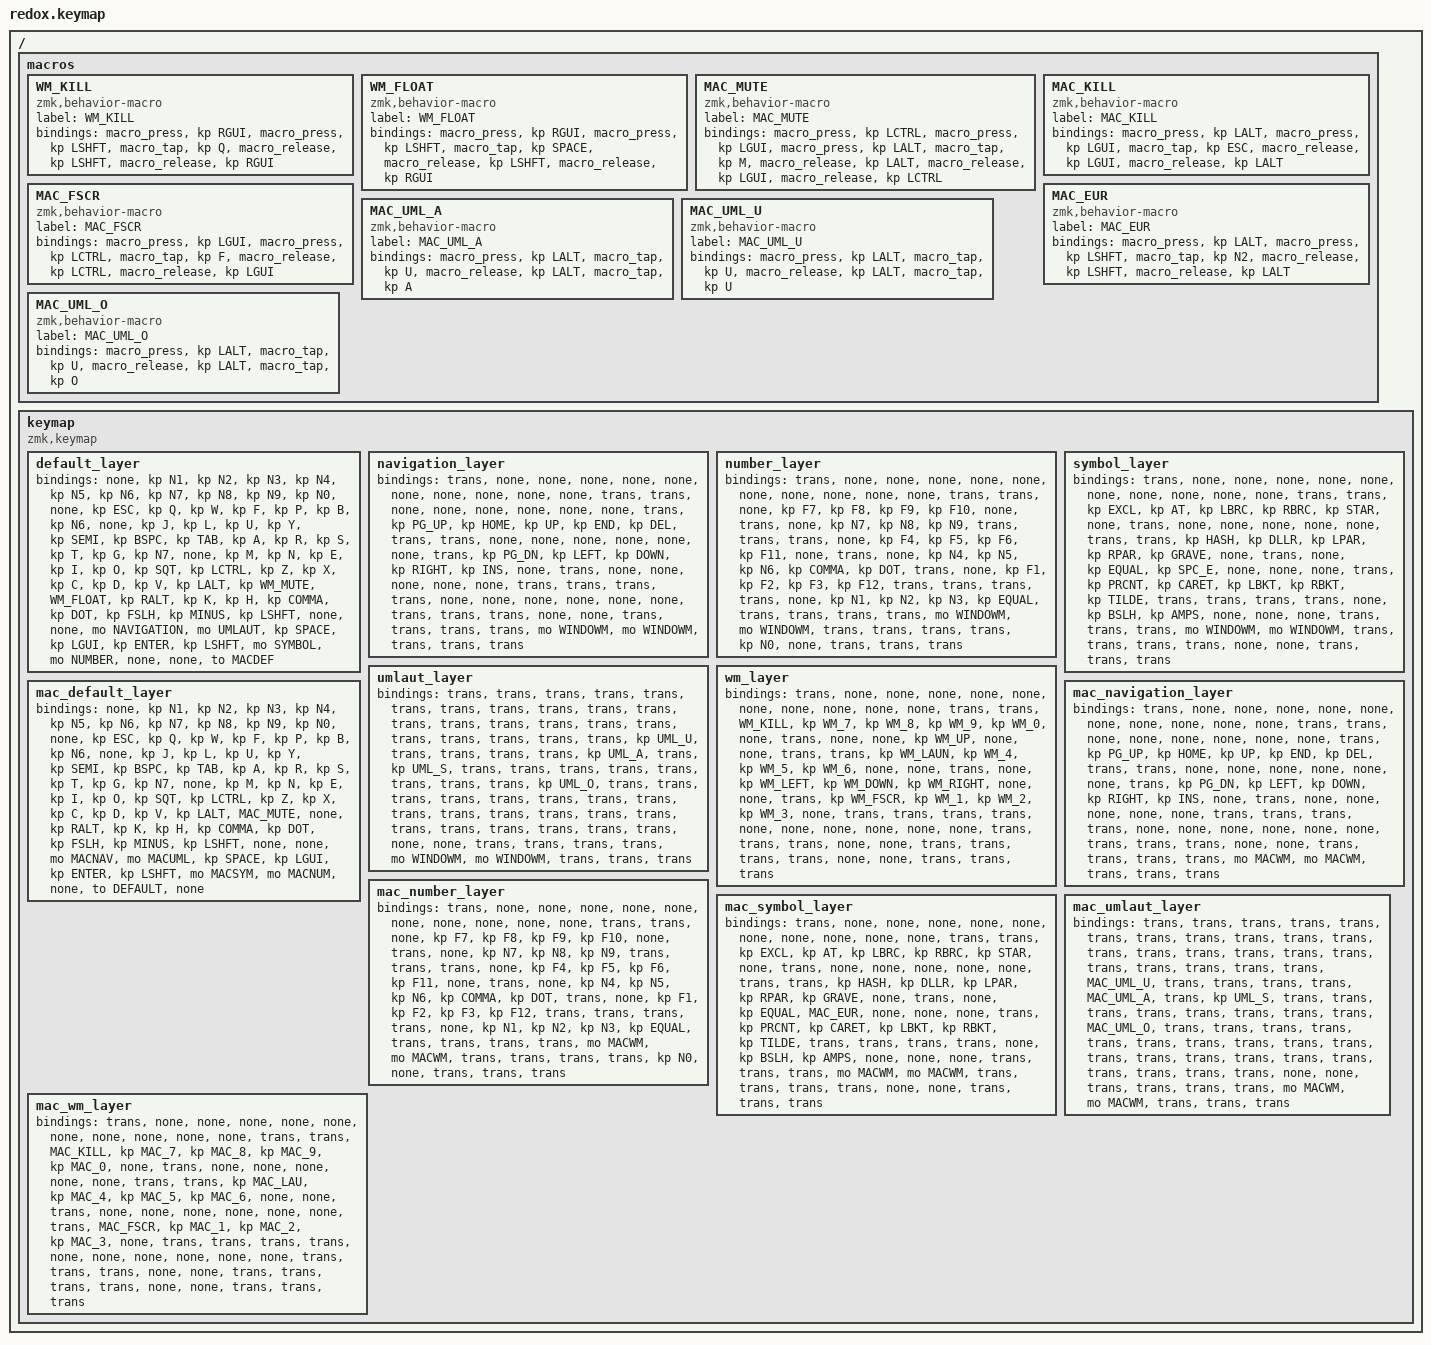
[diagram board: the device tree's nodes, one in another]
/*
 * Copyright (c) 2021 The ZMK Contributors
 *
 * SPDX-License-Identifier: MIT
 */

#include <behaviors.dtsi>
#include <dt-bindings/zmk/keys.h>
#include <dt-bindings/zmk/bt.h>
#include <dt-bindings/zmk/ext_power.h>
#include <dt-bindings/zmk/outputs.h>

#define UML_A RA(Q)
#define UML_S RA(S)
#define UML_U RA(Y)
#define UML_O RA(P)

#define SPC_E RA(N5)

#define WM_MUTE LG(M)

#define WM_UP LG(UP)
#define WM_DOWN LG(DOWN)
#define WM_LEFT LG(LEFT)
#define WM_RIGHT LG(RIGHT)

#define WM_1 LG(N1)
#define WM_2 LG(N2)
#define WM_3 LG(N3)
#define WM_4 LG(N4)
#define WM_5 LG(N5)
#define WM_6 LG(N6)
#define WM_7 LG(N7)
#define WM_8 LG(N8)
#define WM_9 LG(N9)
#define WM_0 LG(N0)

#define MAC_1 LC(N1)
#define MAC_2 LC(N2)
#define MAC_3 LC(N3)
#define MAC_4 LC(N4)
#define MAC_5 LC(N5)
#define MAC_6 LC(N6)
#define MAC_7 LC(N7)
#define MAC_8 LC(N8)
#define MAC_9 LC(N9)
#define MAC_0 LC(N0)

#define WM_LAUN LG(D)
#define WM_FSCR LG(F)

#define MAC_LAU LG(SPACE)

#define DEFAULT    0
#define NAVIGATION 1
#define NUMBER     2
#define SYMBOL     3
#define UMLAUT     4
#define WINDOWM    5
#define MACDEF     6
#define MACNAV     7
#define MACNUM     8
#define MACSYM     9
#define MACUML     10
#define MACWM      11

/ {
    macros {
        WM_KILL: WM_KILL {
            label = "WM_KILL";
            compatible = "zmk,behavior-macro";
            #binding-cells = <0>;
            bindings
                = <&macro_press   &kp RGUI>
                , <&macro_press   &kp LSHFT>
                , <&macro_tap     &kp Q>
                , <&macro_release &kp LSHFT>
                , <&macro_release &kp RGUI>
                ;
        };
        WM_FLOAT: WM_FLOAT {
            label = "WM_FLOAT";
            compatible = "zmk,behavior-macro";
            #binding-cells = <0>;
            bindings
                = <&macro_press   &kp RGUI>
                , <&macro_press   &kp LSHFT>
                , <&macro_tap     &kp SPACE>
                , <&macro_release &kp LSHFT>
                , <&macro_release &kp RGUI>
                ;
        };
        MAC_MUTE: MAC_MUTE {
            label = "MAC_MUTE";
            compatible = "zmk,behavior-macro";
            #binding-cells = <0>;
            bindings
                = <&macro_press   &kp LCTRL>
                , <&macro_press   &kp LGUI>
                , <&macro_press   &kp LALT>
                , <&macro_tap     &kp M>
                , <&macro_release &kp LALT>
                , <&macro_release &kp LGUI>
                , <&macro_release &kp LCTRL>
                ;
        };
        MAC_KILL: MAC_KILL {
            label = "MAC_KILL";
            compatible = "zmk,behavior-macro";
            #binding-cells = <0>;
            bindings
                = <&macro_press   &kp LALT>
                , <&macro_press   &kp LGUI>
                , <&macro_tap     &kp ESC>
                , <&macro_release &kp LGUI>
                , <&macro_release &kp LALT>
                ;
        };
        MAC_FSCR: MAC_FSCR {
            label = "MAC_FSCR";
            compatible = "zmk,behavior-macro";
            #binding-cells = <0>;
            bindings
                = <&macro_press   &kp LGUI>
                , <&macro_press   &kp LCTRL>
                , <&macro_tap     &kp F>
                , <&macro_release &kp LCTRL>
                , <&macro_release &kp LGUI>
                ;
        };
        MAC_EUR: MAC_EUR {
            label = "MAC_EUR";
            compatible = "zmk,behavior-macro";
            #binding-cells = <0>;
            bindings
                = <&macro_press   &kp LALT>
                , <&macro_press   &kp LSHFT>
                , <&macro_tap     &kp N2>
                , <&macro_release &kp LSHFT>
                , <&macro_release &kp LALT>
                ;
        };
        MAC_UML_A: MAC_UML_A {
            label = "MAC_UML_A";
            compatible = "zmk,behavior-macro";
            #binding-cells = <0>;
            bindings
                = <&macro_press   &kp LALT>
                , <&macro_tap     &kp U>
                , <&macro_release &kp LALT>
                , <&macro_tap     &kp A>
                ;
        };
        MAC_UML_U: MAC_UML_U {
            label = "MAC_UML_U";
            compatible = "zmk,behavior-macro";
            #binding-cells = <0>;
            bindings
                = <&macro_press   &kp LALT>
                , <&macro_tap     &kp U>
                , <&macro_release &kp LALT>
                , <&macro_tap     &kp U>
                ;
        };
        MAC_UML_O: MAC_UML_O {
            label = "MAC_UML_O";
            compatible = "zmk,behavior-macro";
            #binding-cells = <0>;
            bindings
                = <&macro_press   &kp LALT>
                , <&macro_tap     &kp U>
                , <&macro_release &kp LALT>
                , <&macro_tap     &kp O>
                ;
        };
    };

    keymap {
        compatible =  "zmk,keymap" ;

        default_layer {
// ----------------------------------------------------------------------------------------------------------------------------------------------------------------
// | ---   |  1      |  2    |   3   |  4     |  5      |                      ---                   |  6        |  7        |  8       |  9     | 0      | ---    |
// | ESC   |  Q      |  W    |   F   |  P     |  B      |   6      |           ---         |  ---    |  J        |  L        |  U       |  Y     | ;      | BKSP   |
// | TAB   |  A      |  R    |   S   |  T     |  G      |   7      |           ---         |  ---    |  M        |  N        |  E       |  I     | O      |  '     |
// | CTRL  |  Z      |  X    |   C   |  D     |  V      |  ALT     | MUTE    | --- | FLOAT |  ALT    |  K        |  H        |  ,       |  .     | /      |  -     |
// | SHIFT | ---     | ---   |      NAV       | UML     | SPACE    |SUPER/CMD| --- | ENTER | SHIFT   | SPEC      |  NUM                 |  ---   | ---    | MAC    |
            bindings = <
   &none     &kp N1   &kp N2   &kp N3 &kp N4   &kp N5                                                  &kp N6      &kp N7      &kp N8    &kp N9   &kp N0   &none
   &kp ESC   &kp Q    &kp W    &kp F  &kp P    &kp B      &kp N6                             &none     &kp J       &kp L       &kp U     &kp Y    &kp SEMI &kp BSPC
   &kp TAB   &kp A    &kp R    &kp S  &kp T    &kp G      &kp N7                             &none     &kp M       &kp N       &kp E     &kp I    &kp O    &kp SQT
   &kp LCTRL &kp Z    &kp X    &kp C  &kp D    &kp V      &kp LALT  &kp WM_MUTE &WM_FLOAT    &kp RALT  &kp K       &kp H       &kp COMMA &kp DOT  &kp FSLH &kp MINUS
   &kp LSHFT &none    &none    &mo NAVIGATION  &mo UMLAUT &kp SPACE &kp LGUI    &kp ENTER    &kp LSHFT &mo SYMBOL  &mo NUMBER            &none    &none    &to MACDEF
            >;

        };
        
        navigation_layer {
// ---------------------------------------------------------------------------------------------------------------------------------
// | ---   | --- | --- |  ---  | --- | --- |                   ---                 |  ---  |  ---  |  ---  |  --- | ---|    ---    |
// | ESC   | --- | --- |  ---  | --- | --- |  ---  |           ---         |  ---  |  PGU  | HOME  |  UP   |  END | DEL|    BKSP   |
// | TAB   | --- | --- |  ---  | --- | --- |  ---  |           ---         |  ---  |  PGD  | LEFT  | DOWN  |RIGHT | INS|    ---    |
// | CTRL  | --- | --- |  ---  | --- | --- |  ALT  | MUTE    | --- | FLOAT |  ALT  |  ---  |  ---  | ---   |  --- | ---|    ---    |
// | SHIFT | --- | --- |  ---        | --- | SPACE |SUPER/CMD| --- | ENTER | SHIFT |  WM   |  WM           |  --- | ---|    ---    |
            bindings = <
   &trans    &none    &none    &none  &none          &none                                                   &none       &none       &none     &none     &none    &trans
   &trans    &none    &none    &none  &none          &none      &none                              &trans    &kp PG_UP   &kp HOME    &kp UP    &kp END   &kp DEL  &trans
   &trans    &none    &none    &none  &none          &none      &none                              &trans    &kp PG_DN   &kp LEFT    &kp DOWN  &kp RIGHT &kp INS  &none
   &trans    &none    &none    &none  &none          &none      &trans    &trans      &trans       &trans    &none       &none       &none     &none     &none    &none
   &trans    &trans   &trans          &none          &none      &trans    &trans      &trans       &trans    &mo WINDOWM &mo WINDOWM           &trans    &trans   &trans
            >;

        };
        
        number_layer {
// ---------------------------------------------------------------------------------------------------------------------------------
// | ---   | --- | --- |  ---  | --- | --- |                   ---                 |  ---  |  ---  |  ---  |  --- | ---|    ---    |
// | ESC   | --- | F7  |  F8   | F9  | F10 |  ---  |           ---         |  ---  |  ---  |  7    |  8    |  9   | ;  |    BKSP   |
// | TAB   | --- | F4  |  F5   | F6  | F11 |  ---  |           ---         |  ---  |  ---  |  4    |  5    |  6   | ,  |     .     |
// | CTRL  | --- | F1  |  F2   | F3  | F12 |  ALT  | MUTE    | --- | FLOAT |  ALT  |  ---  |  1    |  2    |  3   | =  |     -     |
// | SHIFT | --- | --- |  ---  | WM  | WM  | SPACE |SUPER/CMD| --- | ENTER | SHIFT |  0    |  ---  |  ---  |  --- | ---|    ---    |
            bindings = <
   &trans    &none    &none    &none  &none          &none                                                    &none       &none       &none     &none    &none     &trans
   &trans    &none    &kp F7   &kp F8 &kp F9         &kp F10     &none                              &trans    &none       &kp N7      &kp N8    &kp N9   &trans    &trans
   &trans    &none    &kp F4   &kp F5 &kp F6         &kp F11     &none                              &trans    &none       &kp N4      &kp N5    &kp N6   &kp COMMA &kp DOT
   &trans    &none    &kp F1   &kp F2 &kp F3         &kp F12     &trans    &trans      &trans       &trans    &none       &kp N1      &kp N2    &kp N3   &kp EQUAL &trans
   &trans    &trans   &trans          &mo WINDOWM    &mo WINDOWM &trans    &trans      &trans       &trans    &kp N0      &none                 &trans   &trans    &trans
            >;

        };
        
        symbol_layer {
// ---------------------------------------------------------------------------------------------------------------------------------
// | ---   | --- | --- |  ---  | --- | --- |                   ---                 |  ---  |  ---  |  ---  |  --- | ---|    ---    |
// | ESC   |  !  |  @  |   {   |  }  |  *  |  ---  |           ---         |  ---  |  ---  |  ---  |  ---  |  --- | ---|    BKSP   |
// | TAB   |  #  |  $  |   (   |  )  |  `  |  ---  |           ---         |  ---  |  ---  |  =    |  €    |  --- | ---|    ---    |
// | CTRL  |  %  |  ^  |   [   |  ]  |  ~  |  ALT  | MUTE    | --- | FLOAT |  ALT  |  ---  |  \|   |  &    |  --- | ---|    ---    |
// | SHIFT | --- | --- |  ---  | WM  | WM  | SPACE |SUPER/CMD| --- | ENTER | SHIFT |  ---  |  ---  |  ---  |  --- | ---|    ---    |
            bindings = <
   &trans    &none     &none     &none    &none        &none                                                    &none       &none       &none     &none    &none    &trans
   &trans    &kp EXCL  &kp AT    &kp LBRC &kp RBRC     &kp STAR    &none                              &trans    &none       &none       &none     &none    &none    &trans
   &trans    &kp HASH  &kp DLLR  &kp LPAR &kp RPAR     &kp GRAVE   &none                              &trans    &none       &kp EQUAL   &kp SPC_E &none    &none    &none
   &trans    &kp PRCNT &kp CARET &kp LBKT &kp RBKT     &kp TILDE   &trans    &trans      &trans       &trans    &none       &kp BSLH    &kp AMPS  &none    &none    &none
   &trans    &trans    &trans             &mo WINDOWM  &mo WINDOWM &trans    &trans      &trans       &trans    &none       &none                 &trans   &trans   &trans
            >;

        };
        
        umlaut_layer {
// ---------------------------------------------------------------------------------------------------------------------------------
// | ---   |  1  |  2  |   3   |  4  |  5  |                   ---                 |  6    |  7    |  8    |  9   | 0  |    ---    |
// | ESC   |  Q  |  W  |   F   |  P  |  B  |   6   |           ---         |  ---  |  J    |  L    |  Ü    |  Y   | ;  |    BKSP   |
// | TAB   |  Ä  |  R  |   ß   |  T  |  G  |   7   |           ---         |  ---  |  M    |  N    |  E    |  I   | Ö  |     '     |
// | CTRL  |  Z  |  X  |   C   |  D  |  V  |  ALT  | MUTE    | --- | FLOAT |  ALT  |  K    |  H    |  ,    |  .   | /  |     -     |
// | SHIFT | --- | --- |  ---  | --- | --- | SPACE |SUPER/CMD| --- | ENTER | SHIFT |  WM   |  WM   | ---   |  --- | ---|    ---    |
            bindings = <
   &trans    &trans    &trans   &trans    &trans          &trans                                                   &trans       &trans       &trans     &trans    &trans    &trans
   &trans    &trans    &trans   &trans    &trans          &trans      &trans                             &trans    &trans       &trans       &kp UML_U  &trans    &trans    &trans
   &trans    &kp UML_A &trans   &kp UML_S &trans          &trans      &trans                             &trans    &trans       &trans       &trans     &trans    &kp UML_O &trans
   &trans    &trans    &trans   &trans    &trans          &trans      &trans    &trans      &trans       &trans    &trans       &trans       &trans     &trans    &trans    &trans
   &trans    &trans    &trans             &none           &none       &trans    &trans      &trans       &trans    &mo WINDOWM &mo WINDOWM              &trans    &trans    &trans
            >;

        };
        
        wm_layer {
// ---------------------------------------------------------------------------------------------------------------------------------
// | ---   | --- | --- |  ---  | --- | --- |                   ---                 |  ---  |  ---  |  ---  |  --- | ---|    ---    |
// | ESC   | KILL| LA7 |  LA8  | LA9 | LA0 |  ---  |           ---         |  ---  |  ---  |  ---  |  UP   |  --- | ---|    BKSP   |
// | TAB   | LAUN| LA4 |  LA5  | LA6 | --- |  ---  |           ---         |  ---  |  ---  |  LEFT |  DOWN | RIGHT| ---|    ---    |
// | CTRL  | FULL| LA1 |  LA2  | LA3 | --- |  ALT  | MUTE    | --- | FLOAT |  ALT  |  ---  |  ---  |  ---  |  --- | ---|    ---    |
// | SHIFT | --- | --- |  ---  | --- | --- | SPACE |SUPER/CMD| --- | ENTER | SHIFT |  ---  |  ---  |  ---  |  --- | ---|    ---    |
            bindings = <
   &trans    &none       &none    &none    &none          &none                                                   &none       &none       &none       &none        &none    &trans
   &trans    &WM_KILL    &kp WM_7 &kp WM_8 &kp WM_9       &kp WM_0   &none                              &trans    &none       &none       &kp WM_UP   &none        &none    &trans
   &trans    &kp WM_LAUN &kp WM_4 &kp WM_5 &kp WM_6       &none      &none                              &trans    &none       &kp WM_LEFT &kp WM_DOWN &kp WM_RIGHT &none    &none
   &trans    &kp WM_FSCR &kp WM_1 &kp WM_2 &kp WM_3       &none      &trans    &trans      &trans       &trans    &none       &none       &none       &none        &none    &none
   &trans    &trans      &trans            &none          &none      &trans    &trans      &trans       &trans    &none       &none                   &trans       &trans   &trans
            >;

        };
        
        mac_default_layer {
// ----------------------------------------------------------------------------------------------------------------------------------------------------------------------
// | ---   |  1      |  2    |   3   |  4           |  5      |                      ---                   |  6        |  7        |  8       |  9     | 0      | ---    |
// | ESC   |  Q      |  W    |   F   |  P           |  B      |   6      |           ---         |  ---    |  J        |  L        |  U       |  Y     | ;      | BKSP   |
// | TAB   |  A      |  R    |   S   |  T           |  G      |   7      |           ---         |  ---    |  M        |  N        |  E       |  I     | O      |  '     |
// | CTRL  |  Z      |  X    |   C   |  D           |  V      |  ALT     | MUTE    | --- | ---   |  ALT    |  K        |  H        |  ,       |  .     | /      |  -     |
// | SHIFT | ---     | ---   |  ---  | NAV          | UML     | SPACE    |SUPER/CMD| --- | ENTER | SHIFT   | SPEC      |  NUM      | ---      |  ---   | LNX    | ---    |
            bindings = <
   &none     &kp N1   &kp N2   &kp N3 &kp N4         &kp N5                                                   &kp N6      &kp N7      &kp N8    &kp N9   &kp N0      &none
   &kp ESC   &kp Q    &kp W    &kp F  &kp P          &kp B      &kp N6                              &none     &kp J       &kp L       &kp U     &kp Y    &kp SEMI    &kp BSPC
   &kp TAB   &kp A    &kp R    &kp S  &kp T          &kp G      &kp N7                              &none     &kp M       &kp N       &kp E     &kp I    &kp O       &kp SQT
   &kp LCTRL &kp Z    &kp X    &kp C  &kp D          &kp V      &kp LALT  &MAC_MUTE    &none        &kp RALT  &kp K       &kp H       &kp COMMA &kp DOT  &kp FSLH    &kp MINUS
   &kp LSHFT &none    &none           &mo MACNAV     &mo MACUML &kp SPACE &kp LGUI     &kp ENTER    &kp LSHFT &mo MACSYM  &mo MACNUM            &none    &to DEFAULT &none
            >;

        };
        
        mac_navigation_layer {
// ---------------------------------------------------------------------------------------------------------------------------------
// | ---   | --- | --- |  ---  | --- | --- |                   ---                 |  ---  |  ---  |  ---  |  --- | ---|    ---    |
// | ESC   | --- | --- |  ---  | --- | --- |  ---  |           ---         |  ---  |  PGU  | HOME  |  UP   |  END | DEL|    BKSP   |
// | TAB   | --- | --- |  ---  | --- | --- |  ---  |           ---         |  ---  |  PGD  | LEFT  | DOWN  |RIGHT | INS|    ---    |
// | CTRL  | --- | --- |  ---  | --- | --- |  ALT  | MUTE    | --- | FLOAT |  ALT  |  ---  |  ---  | ---   |  --- | ---|    ---    |
// | SHIFT | --- | --- |  ---  | --- | --- | SPACE |SUPER/CMD| --- | ENTER | SHIFT |  WM   |  WM   | ---   |  --- | ---|    ---    |
            bindings = <
   &trans    &none    &none    &none  &none          &none                                                   &none       &none       &none     &none     &none    &trans
   &trans    &none    &none    &none  &none          &none      &none                              &trans    &kp PG_UP   &kp HOME    &kp UP    &kp END   &kp DEL  &trans
   &trans    &none    &none    &none  &none          &none      &none                              &trans    &kp PG_DN   &kp LEFT    &kp DOWN  &kp RIGHT &kp INS  &none
   &trans    &none    &none    &none  &none          &none      &trans    &trans      &trans       &trans    &none       &none       &none     &none     &none    &none
   &trans    &trans   &trans          &none          &none      &trans    &trans      &trans       &trans    &mo MACWM   &mo MACWM             &trans    &trans   &trans
            >;

        };
        
        mac_number_layer {
// ---------------------------------------------------------------------------------------------------------------------------------
// | ---   | --- | --- |  ---  | --- | --- |                   ---                 |  ---  |  ---  |  ---  |  --- | ---|    ---    |
// | ESC   | --- | F7  |  F8   | F9  | F10 |  ---  |           ---         |  ---  |  ---  |  7    |  8    |  9   | ;  |    BKSP   |
// | TAB   | --- | F4  |  F5   | F6  | F11 |  ---  |           ---         |  ---  |  ---  |  4    |  5    |  6   | ,  |     .     |
// | CTRL  | --- | F1  |  F2   | F3  | F12 |  ALT  | MUTE    | --- | FLOAT |  ALT  |  ---  |  1    |  2    |  3   | =  |     -     |
// | SHIFT | --- | --- |  ---  | WM  | WM  | SPACE |SUPER/CMD| --- | ENTER | SHIFT |  0    |  ---  |  ---  |  --- | ---|    ---    |
            bindings = <
   &trans    &none    &none    &none  &none          &none                                                    &none       &none       &none     &none    &none     &trans
   &trans    &none    &kp F7   &kp F8 &kp F9         &kp F10     &none                              &trans    &none       &kp N7      &kp N8    &kp N9   &trans    &trans
   &trans    &none    &kp F4   &kp F5 &kp F6         &kp F11     &none                              &trans    &none       &kp N4      &kp N5    &kp N6   &kp COMMA &kp DOT
   &trans    &none    &kp F1   &kp F2 &kp F3         &kp F12     &trans    &trans      &trans       &trans    &none       &kp N1      &kp N2    &kp N3   &kp EQUAL &trans
   &trans    &trans   &trans          &mo MACWM      &mo MACWM   &trans    &trans      &trans       &trans    &kp N0      &none                 &trans   &trans    &trans
            >;

        };
        
        mac_symbol_layer {
// ---------------------------------------------------------------------------------------------------------------------------------
// | ---   | --- | --- |  ---  | --- | --- |                   ---                 |  ---  |  ---  |  ---  |  --- | ---|    ---    |
// | ESC   |  !  |  @  |   {   |  }  |  *  |  ---  |           ---         |  ---  |  ---  |  ---  |  ---  |  --- | ---|    BKSP   |
// | TAB   |  #  |  $  |   (   |  )  |  `  |  ---  |           ---         |  ---  |  ---  |  =    |  €    |  --- | ---|    ---    |
// | CTRL  |  %  |  ^  |   [   |  ]  |  ~  |  ALT  | MUTE    | --- | FLOAT |  ALT  |  ---  |  \|   |  &    |  --- | ---|    ---    |
// | SHIFT | --- | --- |  ---  | WM  | WM  | SPACE |SUPER/CMD| --- | ENTER | SHIFT |  ---  |  ---  |  ---  |  --- | ---|    ---    |
            bindings = <
   &trans    &none     &none     &none    &none        &none                                                    &none       &none       &none     &none    &none    &trans
   &trans    &kp EXCL  &kp AT    &kp LBRC &kp RBRC     &kp STAR    &none                              &trans    &none       &none       &none     &none    &none    &trans
   &trans    &kp HASH  &kp DLLR  &kp LPAR &kp RPAR     &kp GRAVE   &none                              &trans    &none       &kp EQUAL   &MAC_EUR  &none    &none    &none
   &trans    &kp PRCNT &kp CARET &kp LBKT &kp RBKT     &kp TILDE   &trans    &trans      &trans       &trans    &none       &kp BSLH    &kp AMPS  &none    &none    &none
   &trans    &trans    &trans             &mo MACWM    &mo MACWM   &trans    &trans      &trans       &trans    &none       &none                 &trans   &trans   &trans
            >;

        };
        
        mac_umlaut_layer {
// ---------------------------------------------------------------------------------------------------------------------------------
// | ---   |  1  |  2  |   3   |  4  |  5  |                   ---                 |  6    |  7    |  8    |  9   | 0  |    ---    |
// | ESC   |  Q  |  W  |   F   |  P  |  B  |   6   |           ---         |  ---  |  J    |  L    |  Ü    |  Y   | ;  |    BKSP   |
// | TAB   |  Ä  |  R  |   ß   |  T  |  G  |   7   |           ---         |  ---  |  M    |  N    |  E    |  I   | Ö  |     '     |
// | CTRL  |  Z  |  X  |   C   |  D  |  V  |  ALT  | MUTE    | --- | FLOAT |  ALT  |  K    |  H    |  ,    |  .   | /  |     -     |
// | SHIFT | --- | --- |  ---  | --- | --- | SPACE |SUPER/CMD| --- | ENTER | SHIFT |  WM   |  WM   | ---   |  --- | ---|    ---    |
            bindings = <
   &trans    &trans     &trans   &trans    &trans          &trans                                                   &trans       &trans       &trans     &trans    &trans     &trans
   &trans    &trans     &trans   &trans    &trans          &trans      &trans                             &trans    &trans       &trans       &MAC_UML_U &trans    &trans     &trans
   &trans    &MAC_UML_A &trans   &kp UML_S &trans          &trans      &trans                             &trans    &trans       &trans       &trans     &trans    &MAC_UML_O &trans
   &trans    &trans     &trans   &trans    &trans          &trans      &trans    &trans      &trans       &trans    &trans       &trans       &trans     &trans    &trans     &trans
   &trans    &trans     &trans             &none           &none       &trans    &trans      &trans       &trans    &mo MACWM   &mo MACWM                &trans    &trans     &trans
            >;

        };
        
        mac_wm_layer {
// ---------------------------------------------------------------------------------------------------------------------------------
// | ---   | --- | --- |  ---  | --- | --- |                   ---                 |  ---  |  ---  |  ---  |  --- | ---|    ---    |
// | ESC   | KILL| LA7 |  LA8  | LA9 | LA0 |  ---  |           ---         |  ---  |  ---  |  ---  |  UP   |  --- | ---|    BKSP   |
// | TAB   | LAUN| LA4 |  LA5  | LA6 | --- |  ---  |           ---         |  ---  |  ---  |  LEFT |  DOWN | RIGHT| ---|    ---    |
// | CTRL  | FULL| LA1 |  LA2  | LA3 | --- |  ALT  | MUTE    | --- | FLOAT |  ALT  |  ---  |  ---  |  ---  |  --- | ---|    ---    |
// | SHIFT | --- | --- |  ---  | --- | --- | SPACE |SUPER/CMD| --- | ENTER | SHIFT |  ---  |  ---  |  ---  |  --- | ---|    ---    |
            bindings = <
   &trans    &none       &none     &none     &none          &none                                                   &none       &none       &none       &none        &none    &trans
   &trans    &MAC_KILL   &kp MAC_7 &kp MAC_8 &kp MAC_9      &kp MAC_0  &none                              &trans    &none       &none       &none       &none        &none    &trans
   &trans    &kp MAC_LAU &kp MAC_4 &kp MAC_5 &kp MAC_6      &none      &none                              &trans    &none       &none       &none       &none        &none    &none
   &trans    &MAC_FSCR   &kp MAC_1 &kp MAC_2 &kp MAC_3      &none      &trans    &trans      &trans       &trans    &none       &none       &none       &none        &none    &none
   &trans    &trans      &trans              &none          &none      &trans    &trans      &trans       &trans    &none       &none                   &trans       &trans   &trans
            >;

        };

    };
};
